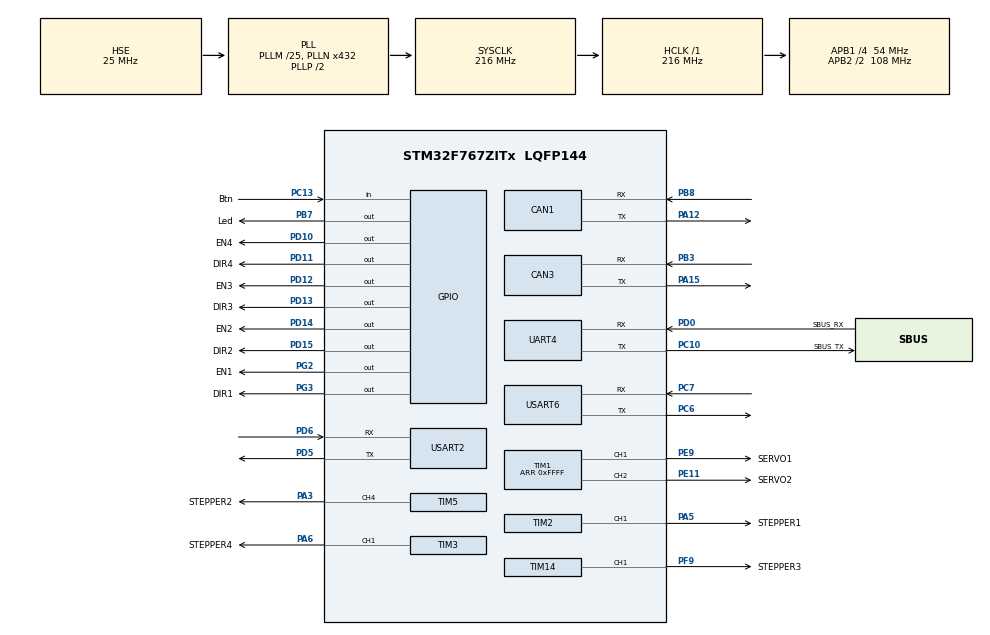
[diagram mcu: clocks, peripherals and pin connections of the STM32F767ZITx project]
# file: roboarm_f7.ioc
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CAN1.BS1=CAN_BS1_4TQ
CAN1.BS2=CAN_BS2_3TQ
CAN1.CalculateTimeQuantum=296.2962962962963
CAN3.BS1=CAN_BS1_4TQ
CAN3.BS2=CAN_BS2_3TQ
CAN3.CalculateTimeQuantum=296.2962962962963
Mcu.Family=STM32F7
Mcu.Name=STM32F767ZITx
Mcu.Package=LQFP144
NVIC.PriorityGroup=NVIC_PRIORITYGROUP_4
NVIC.TIM1_CC_IRQn=true\:0\:0\:false\:false\:true\:true\:true
PA12.Mode=Master
PA12.Signal=CAN1_TX
PA15.Mode=Master
PA15.Signal=CAN3_TX
PA3.GPIO_Label=STEPPER2
PA3.Signal=S_TIM5_CH4
PA5.GPIO_Label=STEPPER1
PA5.Signal=S_TIM2_CH1_ETR
PA6.GPIO_Label=STEPPER4
PA6.Signal=S_TIM3_CH1
PB3.Mode=Master
PB3.Signal=CAN3_RX
PB7.GPIO_FM7=__NULL
PB7.GPIO_Label=Led
PB7.GPIO_ModeDefaultOutputPP=GPIO_MODE_OUTPUT_PP
PB7.GPIO_PuPd=GPIO_NOPULL
PB7.GPIO_Speed=GPIO_SPEED_FREQ_LOW
PB7.PinState=GPIO_PIN_RESET
PB7.Signal=GPIO_Output
PB8.Mode=Master
PB8.Signal=CAN1_RX
PC10.GPIO_Label=SBUS_TX
PC10.Mode=Asynchronous
PC10.Signal=UART4_TX
PC13.GPIO_Label=Btn
PC13.GPIO_Mode=GPIO_MODE_INPUT
PC13.GPIO_PuPd=GPIO_NOPULL
PC13.Signal=GPIO_Input
PC6.Mode=Asynchronous
PC6.Signal=USART6_TX
PC7.Mode=Asynchronous
PC7.Signal=USART6_RX
PD0.GPIO_Label=SBUS_RX
PD0.Mode=Asynchronous
PD0.Signal=UART4_RX
PD10.GPIO_Label=EN4
PD10.Signal=GPIO_Output
PD11.GPIO_Label=DIR4
PD11.Signal=GPIO_Output
PD12.GPIO_Label=EN3
PD12.Signal=GPIO_Output
PD13.GPIO_Label=DIR3
PD13.Signal=GPIO_Output
PD14.GPIO_Label=EN2
PD14.Signal=GPIO_Output
PD15.GPIO_Label=DIR2
PD15.Signal=GPIO_Output
PD5.Mode=Asynchronous
PD5.Signal=USART2_TX
PD6.Mode=Asynchronous
PD6.Signal=USART2_RX
PE11.GPIO_Label=SERVO2
PE11.Signal=S_TIM1_CH2
PE9.GPIO_Label=SERVO1
PE9.Signal=S_TIM1_CH1
PF9.GPIO_Label=STEPPER3
PF9.Signal=S_TIM14_CH1
PG2.GPIO_Label=EN1
PG2.Signal=GPIO_Output
PG3.GPIO_Label=DIR1
PG3.Signal=GPIO_Output
PH0/OSC_IN.Mode=HSE-External-Oscillator
PH0/OSC_IN.Signal=RCC_OSC_IN
PH1/OSC_OUT.Mode=HSE-External-Oscillator
PH1/OSC_OUT.Signal=RCC_OSC_OUT
ProjectManager.HeapSize=0x200
ProjectManager.StackSize=0x400
ProjectManager.TargetToolchain=MDK-ARM V5
RCC.AHBFreq_Value=216000000
RCC.APB1CLKDivider=RCC_HCLK_DIV4
RCC.APB1Freq_Value=54000000
RCC.APB1TimFreq_Value=108000000
RCC.APB2CLKDivider=RCC_HCLK_DIV2
RCC.APB2Freq_Value=108000000
RCC.APB2TimFreq_Value=216000000
RCC.CortexFreq_Value=216000000
RCC.HCLKFreq_Value=216000000
RCC.HSE_VALUE=25000000
RCC.HSI_VALUE=16000000
RCC.LSE_VALUE=32768
RCC.PLLM=25
RCC.PLLN=432
RCC.PLLSourceVirtual=RCC_PLLSOURCE_HSE
RCC.SYSCLKFreq_VALUE=216000000
RCC.SYSCLKSource=RCC_SYSCLKSOURCE_PLLCLK
RCC.USBFreq_Value=216000000
RCC.VCOOutputFreq_Value=432000000
SH.S_TIM14_CH1.0=TIM14_CH1,PWM Generation1 CH1
SH.S_TIM1_CH1.0=TIM1_CH1,PWM Generation1 CH1
SH.S_TIM1_CH2.0=TIM1_CH2,PWM Generation2 CH2
SH.S_TIM2_CH1_ETR.0=TIM2_CH1,PWM Generation1 CH1
SH.S_TIM3_CH1.0=TIM3_CH1,PWM Generation1 CH1
SH.S_TIM5_CH4.0=TIM5_CH4,PWM Generation4 CH4
TIM1.Channel-PWM\ Generation1\ CH1=TIM_CHANNEL_1
TIM1.Channel-PWM\ Generation2\ CH2=TIM_CHANNEL_2
TIM1.Period=0xFFFF
TIM14.Channel=TIM_CHANNEL_1
TIM14.Prescaler=0xFFFF
TIM2.Channel-PWM\ Generation1\ CH1=TIM_CHANNEL_1
TIM2.Period=0xFFFF
TIM3.Channel-PWM\ Generation1\ CH1=TIM_CHANNEL_1
TIM3.Period=0xFFFF
TIM3.Prescaler=0x0
TIM5.Channel-PWM\ Generation4\ CH4=TIM_CHANNEL_4
TIM5.Period=0xFFFF
USART2.VirtualMode-Asynchronous=VM_ASYNC
USART6.VirtualMode-Asynchronous=VM_ASYNC
VP_TIM14_VS_ClockSourceINT.Mode=Enable_Timer
VP_TIM1_VS_ClockSourceINT.Mode=Internal
VP_TIM2_VS_ClockSourceINT.Mode=Internal
VP_TIM3_VS_ClockSourceINT.Mode=Internal
VP_TIM5_VS_ClockSourceINT.Mode=Internal
board=custom

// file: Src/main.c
/* USER CODE BEGIN Header */
/**
  ******************************************************************************
  * @file           : main.c
  * @brief          : Main program body
  ******************************************************************************
  * @attention
  *
  * <h2><center>&copy; Copyright (c) 2020 STMicroelectronics.
  * All rights reserved.</center></h2>
  *
  * This software component is licensed by ST under BSD 3-Clause license,
  * the "License"; You may not use this file except in compliance with the
  * License. You may obtain a copy of the License at:
  *                        opensource.org/licenses/BSD-3-Clause
  *
  ******************************************************************************
  */
/* USER CODE END Header */

#include "main.h"

CAN_HandleTypeDef hcan1;
CAN_HandleTypeDef hcan3;

TIM_HandleTypeDef htim1;
TIM_HandleTypeDef htim2;
TIM_HandleTypeDef htim3;
TIM_HandleTypeDef htim5;
TIM_HandleTypeDef htim14;

UART_HandleTypeDef huart4;
UART_HandleTypeDef huart2;
UART_HandleTypeDef huart6;

void SystemClock_Config(void);
static void MX_GPIO_Init(void);
static void MX_USART2_UART_Init(void);
static void MX_CAN1_Init(void);
static void MX_CAN3_Init(void);
static void MX_TIM1_Init(void);
static void MX_TIM2_Init(void);
static void MX_TIM3_Init(void);
static void MX_TIM5_Init(void);
static void MX_TIM14_Init(void);
static void MX_UART4_Init(void);
static void MX_USART6_UART_Init(void);

int main(void)
{
  /* USER CODE BEGIN 1 */
  int test = 0;
  int test2 = 0;
  /* USER CODE END 1 */

  /* MCU Configuration--------------------------------------------------------*/

  /* Reset of all peripherals, Initializes the Flash interface and the Systick. */
  HAL_Init();

  /* Configure the system clock */
  SystemClock_Config();

  /* Initialize all configured peripherals */
  MX_GPIO_Init();
  MX_USART2_UART_Init();
  MX_CAN1_Init();
  MX_CAN3_Init();
  MX_TIM1_Init();
  MX_TIM2_Init();
  MX_TIM3_Init();
  MX_TIM5_Init();
  MX_TIM14_Init();
  MX_UART4_Init();
  MX_USART6_UART_Init();

  /* Infinite loop */
  /* USER CODE BEGIN WHILE */
  while (1)
  {
    test = HAL_GetTick();
    test2 = 0;

    if((test != test2) == 0)
    {
      //HAL_GPIO_WritePin(Led_GPIO_Port, Led_Pin, GPIO_PIN_SET);
      HAL_GPIO_TogglePin(Led_GPIO_Port, Led_Pin);
      test2 = test;
      //HAL_UART_Transmit(&huart2, (uint8_t*)"ON\r\n", 3, 0xFFFF);
      //HAL_UART_Transmit(&huart6, (uint8_t*)"ON\r\n", 3, 0xFFFF);
    }
    else
    {
      //HAL_GPIO_WritePin(Led_GPIO_Port, Led_Pin, GPIO_PIN_RESET);
      //HAL_UART_Transmit(&huart2, (uint8_t*)"OFF\r\n", 4, 0xFFFF);
      //HAL_UART_Transmit(&huart6, (uint8_t*)"OFF\r\n", 4, 0xFFFF);
    }
    //HAL_Delay(100);
    /* USER CODE END WHILE */

  }
}

void SystemClock_Config(void)
{
  RCC_OscInitTypeDef RCC_OscInitStruct = {0};
  RCC_ClkInitTypeDef RCC_ClkInitStruct = {0};
  RCC_PeriphCLKInitTypeDef PeriphClkInitStruct = {0};

  /** Configure the main internal regulator output voltage
  */
  __HAL_RCC_PWR_CLK_ENABLE();
  __HAL_PWR_VOLTAGESCALING_CONFIG(PWR_REGULATOR_VOLTAGE_SCALE1);
  /** Initializes the CPU, AHB and APB busses clocks
  */
  RCC_OscInitStruct.OscillatorType = RCC_OSCILLATORTYPE_HSE;
  RCC_OscInitStruct.HSEState = RCC_HSE_ON;
  RCC_OscInitStruct.PLL.PLLState = RCC_PLL_ON;
  RCC_OscInitStruct.PLL.PLLSource = RCC_PLLSOURCE_HSE;
  RCC_OscInitStruct.PLL.PLLM = 25;
  RCC_OscInitStruct.PLL.PLLN = 432;
  RCC_OscInitStruct.PLL.PLLP = RCC_PLLP_DIV2;
  RCC_OscInitStruct.PLL.PLLQ = 2;
  if (HAL_RCC_OscConfig(&RCC_OscInitStruct) != HAL_OK)
  {
    Error_Handler();
  }
  /** Activate the Over-Drive mode
  */
  if (HAL_PWREx_EnableOverDrive() != HAL_OK)
  {
    Error_Handler();
  }
  /** Initializes the CPU, AHB and APB busses clocks
  */
  RCC_ClkInitStruct.ClockType = RCC_CLOCKTYPE_HCLK|RCC_CLOCKTYPE_SYSCLK
                              |RCC_CLOCKTYPE_PCLK1|RCC_CLOCKTYPE_PCLK2;
  RCC_ClkInitStruct.SYSCLKSource = RCC_SYSCLKSOURCE_PLLCLK;
  RCC_ClkInitStruct.AHBCLKDivider = RCC_SYSCLK_DIV1;
  RCC_ClkInitStruct.APB1CLKDivider = RCC_HCLK_DIV4;
  RCC_ClkInitStruct.APB2CLKDivider = RCC_HCLK_DIV2;

  if (HAL_RCC_ClockConfig(&RCC_ClkInitStruct, FLASH_LATENCY_7) != HAL_OK)
  {
    Error_Handler();
  }
  PeriphClkInitStruct.PeriphClockSelection = RCC_PERIPHCLK_USART2|RCC_PERIPHCLK_USART6
                              |RCC_PERIPHCLK_UART4;
  PeriphClkInitStruct.Usart2ClockSelection = RCC_USART2CLKSOURCE_PCLK1;
  PeriphClkInitStruct.Uart4ClockSelection = RCC_UART4CLKSOURCE_PCLK1;
  PeriphClkInitStruct.Usart6ClockSelection = RCC_USART6CLKSOURCE_PCLK2;
  if (HAL_RCCEx_PeriphCLKConfig(&PeriphClkInitStruct) != HAL_OK)
  {
    Error_Handler();
  }
}

static void MX_CAN1_Init(void)
{

  hcan1.Instance = CAN1;
  hcan1.Init.Prescaler = 16;
  hcan1.Init.Mode = CAN_MODE_NORMAL;
  hcan1.Init.SyncJumpWidth = CAN_SJW_1TQ;
  hcan1.Init.TimeSeg1 = CAN_BS1_4TQ;
  hcan1.Init.TimeSeg2 = CAN_BS2_3TQ;
  hcan1.Init.TimeTriggeredMode = DISABLE;
  hcan1.Init.AutoBusOff = DISABLE;
  hcan1.Init.AutoWakeUp = DISABLE;
  hcan1.Init.AutoRetransmission = DISABLE;
  hcan1.Init.ReceiveFifoLocked = DISABLE;
  hcan1.Init.TransmitFifoPriority = DISABLE;
  if (HAL_CAN_Init(&hcan1) != HAL_OK)
  {
    Error_Handler();
  }

}

static void MX_CAN3_Init(void)
{

  hcan3.Instance = CAN3;
  hcan3.Init.Prescaler = 16;
  hcan3.Init.Mode = CAN_MODE_NORMAL;
  hcan3.Init.SyncJumpWidth = CAN_SJW_1TQ;
  hcan3.Init.TimeSeg1 = CAN_BS1_4TQ;
  hcan3.Init.TimeSeg2 = CAN_BS2_3TQ;
  hcan3.Init.TimeTriggeredMode = DISABLE;
  hcan3.Init.AutoBusOff = DISABLE;
  hcan3.Init.AutoWakeUp = DISABLE;
  hcan3.Init.AutoRetransmission = DISABLE;
  hcan3.Init.ReceiveFifoLocked = DISABLE;
  hcan3.Init.TransmitFifoPriority = DISABLE;
  if (HAL_CAN_Init(&hcan3) != HAL_OK)
  {
    Error_Handler();
  }

}

static void MX_TIM1_Init(void)
{

  TIM_ClockConfigTypeDef sClockSourceConfig = {0};
  TIM_MasterConfigTypeDef sMasterConfig = {0};
  TIM_OC_InitTypeDef sConfigOC = {0};
  TIM_BreakDeadTimeConfigTypeDef sBreakDeadTimeConfig = {0};

  htim1.Instance = TIM1;
  htim1.Init.Prescaler = 0;
  htim1.Init.CounterMode = TIM_COUNTERMODE_UP;
  htim1.Init.Period = 0xFFFF;
  htim1.Init.ClockDivision = TIM_CLOCKDIVISION_DIV1;
  htim1.Init.RepetitionCounter = 0;
  htim1.Init.AutoReloadPreload = TIM_AUTORELOAD_PRELOAD_DISABLE;
  if (HAL_TIM_Base_Init(&htim1) != HAL_OK)
  {
    Error_Handler();
  }
  sClockSourceConfig.ClockSource = TIM_CLOCKSOURCE_INTERNAL;
  if (HAL_TIM_ConfigClockSource(&htim1, &sClockSourceConfig) != HAL_OK)
  {
    Error_Handler();
  }
  if (HAL_TIM_PWM_Init(&htim1) != HAL_OK)
  {
    Error_Handler();
  }
  sMasterConfig.MasterOutputTrigger = TIM_TRGO_RESET;
  sMasterConfig.MasterOutputTrigger2 = TIM_TRGO2_RESET;
  sMasterConfig.MasterSlaveMode = TIM_MASTERSLAVEMODE_DISABLE;
  if (HAL_TIMEx_MasterConfigSynchronization(&htim1, &sMasterConfig) != HAL_OK)
  {
    Error_Handler();
  }
  sConfigOC.OCMode = TIM_OCMODE_PWM1;
  sConfigOC.Pulse = 0;
  sConfigOC.OCPolarity = TIM_OCPOLARITY_HIGH;
  sConfigOC.OCNPolarity = TIM_OCNPOLARITY_HIGH;
  sConfigOC.OCFastMode = TIM_OCFAST_DISABLE;
  sConfigOC.OCIdleState = TIM_OCIDLESTATE_RESET;
  sConfigOC.OCNIdleState = TIM_OCNIDLESTATE_RESET;
  if (HAL_TIM_PWM_ConfigChannel(&htim1, &sConfigOC, TIM_CHANNEL_1) != HAL_OK)
  {
    Error_Handler();
  }
  if (HAL_TIM_PWM_ConfigChannel(&htim1, &sConfigOC, TIM_CHANNEL_2) != HAL_OK)
  {
    Error_Handler();
  }
  sBreakDeadTimeConfig.OffStateRunMode = TIM_OSSR_DISABLE;
  sBreakDeadTimeConfig.OffStateIDLEMode = TIM_OSSI_DISABLE;
  sBreakDeadTimeConfig.LockLevel = TIM_LOCKLEVEL_OFF;
  sBreakDeadTimeConfig.DeadTime = 0;
  sBreakDeadTimeConfig.BreakState = TIM_BREAK_DISABLE;
  sBreakDeadTimeConfig.BreakPolarity = TIM_BREAKPOLARITY_HIGH;
  sBreakDeadTimeConfig.BreakFilter = 0;
  sBreakDeadTimeConfig.Break2State = TIM_BREAK2_DISABLE;
  sBreakDeadTimeConfig.Break2Polarity = TIM_BREAK2POLARITY_HIGH;
  sBreakDeadTimeConfig.Break2Filter = 0;
  sBreakDeadTimeConfig.AutomaticOutput = TIM_AUTOMATICOUTPUT_DISABLE;
  if (HAL_TIMEx_ConfigBreakDeadTime(&htim1, &sBreakDeadTimeConfig) != HAL_OK)
  {
    Error_Handler();
  }
  HAL_TIM_MspPostInit(&htim1);

}

static void MX_TIM2_Init(void)
{

  TIM_ClockConfigTypeDef sClockSourceConfig = {0};
  TIM_MasterConfigTypeDef sMasterConfig = {0};
  TIM_OC_InitTypeDef sConfigOC = {0};

  htim2.Instance = TIM2;
  htim2.Init.Prescaler = 0;
  htim2.Init.CounterMode = TIM_COUNTERMODE_UP;
  htim2.Init.Period = 0xFFFF;
  htim2.Init.ClockDivision = TIM_CLOCKDIVISION_DIV1;
  htim2.Init.AutoReloadPreload = TIM_AUTORELOAD_PRELOAD_DISABLE;
  if (HAL_TIM_Base_Init(&htim2) != HAL_OK)
  {
    Error_Handler();
  }
  sClockSourceConfig.ClockSource = TIM_CLOCKSOURCE_INTERNAL;
  if (HAL_TIM_ConfigClockSource(&htim2, &sClockSourceConfig) != HAL_OK)
  {
    Error_Handler();
  }
  if (HAL_TIM_PWM_Init(&htim2) != HAL_OK)
  {
    Error_Handler();
  }
  sMasterConfig.MasterOutputTrigger = TIM_TRGO_RESET;
  sMasterConfig.MasterSlaveMode = TIM_MASTERSLAVEMODE_DISABLE;
  if (HAL_TIMEx_MasterConfigSynchronization(&htim2, &sMasterConfig) != HAL_OK)
  {
    Error_Handler();
  }
  sConfigOC.OCMode = TIM_OCMODE_PWM1;
  sConfigOC.Pulse = 0;
  sConfigOC.OCPolarity = TIM_OCPOLARITY_HIGH;
  sConfigOC.OCFastMode = TIM_OCFAST_DISABLE;
  if (HAL_TIM_PWM_ConfigChannel(&htim2, &sConfigOC, TIM_CHANNEL_1) != HAL_OK)
  {
    Error_Handler();
  }
  HAL_TIM_MspPostInit(&htim2);

}

static void MX_TIM3_Init(void)
{

  TIM_ClockConfigTypeDef sClockSourceConfig = {0};
  TIM_MasterConfigTypeDef sMasterConfig = {0};
  TIM_OC_InitTypeDef sConfigOC = {0};

  htim3.Instance = TIM3;
  htim3.Init.Prescaler = 0x0;
  htim3.Init.CounterMode = TIM_COUNTERMODE_UP;
  htim3.Init.Period = 0xFFFF;
  htim3.Init.ClockDivision = TIM_CLOCKDIVISION_DIV1;
  htim3.Init.AutoReloadPreload = TIM_AUTORELOAD_PRELOAD_DISABLE;
  if (HAL_TIM_Base_Init(&htim3) != HAL_OK)
  {
    Error_Handler();
  }
  sClockSourceConfig.ClockSource = TIM_CLOCKSOURCE_INTERNAL;
  if (HAL_TIM_ConfigClockSource(&htim3, &sClockSourceConfig) != HAL_OK)
  {
    Error_Handler();
  }
  if (HAL_TIM_PWM_Init(&htim3) != HAL_OK)
  {
    Error_Handler();
  }
  sMasterConfig.MasterOutputTrigger = TIM_TRGO_RESET;
  sMasterConfig.MasterSlaveMode = TIM_MASTERSLAVEMODE_DISABLE;
  if (HAL_TIMEx_MasterConfigSynchronization(&htim3, &sMasterConfig) != HAL_OK)
  {
    Error_Handler();
  }
  sConfigOC.OCMode = TIM_OCMODE_PWM1;
  sConfigOC.Pulse = 0;
  sConfigOC.OCPolarity = TIM_OCPOLARITY_HIGH;
  sConfigOC.OCFastMode = TIM_OCFAST_DISABLE;
  if (HAL_TIM_PWM_ConfigChannel(&htim3, &sConfigOC, TIM_CHANNEL_1) != HAL_OK)
  {
    Error_Handler();
  }
  HAL_TIM_MspPostInit(&htim3);

}

static void MX_TIM5_Init(void)
{

  TIM_ClockConfigTypeDef sClockSourceConfig = {0};
  TIM_MasterConfigTypeDef sMasterConfig = {0};
  TIM_OC_InitTypeDef sConfigOC = {0};

  htim5.Instance = TIM5;
  htim5.Init.Prescaler = 0;
  htim5.Init.CounterMode = TIM_COUNTERMODE_UP;
  htim5.Init.Period = 0xFFFF;
  htim5.Init.ClockDivision = TIM_CLOCKDIVISION_DIV1;
  htim5.Init.AutoReloadPreload = TIM_AUTORELOAD_PRELOAD_DISABLE;
  if (HAL_TIM_Base_Init(&htim5) != HAL_OK)
  {
    Error_Handler();
  }
  sClockSourceConfig.ClockSource = TIM_CLOCKSOURCE_INTERNAL;
  if (HAL_TIM_ConfigClockSource(&htim5, &sClockSourceConfig) != HAL_OK)
  {
    Error_Handler();
  }
  if (HAL_TIM_PWM_Init(&htim5) != HAL_OK)
  {
    Error_Handler();
  }
  sMasterConfig.MasterOutputTrigger = TIM_TRGO_RESET;
  sMasterConfig.MasterSlaveMode = TIM_MASTERSLAVEMODE_DISABLE;
  if (HAL_TIMEx_MasterConfigSynchronization(&htim5, &sMasterConfig) != HAL_OK)
  {
    Error_Handler();
  }
  sConfigOC.OCMode = TIM_OCMODE_PWM1;
  sConfigOC.Pulse = 0;
  sConfigOC.OCPolarity = TIM_OCPOLARITY_HIGH;
  sConfigOC.OCFastMode = TIM_OCFAST_DISABLE;
  if (HAL_TIM_PWM_ConfigChannel(&htim5, &sConfigOC, TIM_CHANNEL_4) != HAL_OK)
  {
    Error_Handler();
  }
  HAL_TIM_MspPostInit(&htim5);

}

static void MX_TIM14_Init(void)
{

  TIM_OC_InitTypeDef sConfigOC = {0};

  htim14.Instance = TIM14;
  htim14.Init.Prescaler = 0xFFFF;
  htim14.Init.CounterMode = TIM_COUNTERMODE_UP;
  htim14.Init.Period = 0;
  htim14.Init.ClockDivision = TIM_CLOCKDIVISION_DIV1;
  htim14.Init.AutoReloadPreload = TIM_AUTORELOAD_PRELOAD_DISABLE;
  if (HAL_TIM_Base_Init(&htim14) != HAL_OK)
  {
    Error_Handler();
  }
  if (HAL_TIM_PWM_Init(&htim14) != HAL_OK)
  {
    Error_Handler();
  }
  sConfigOC.OCMode = TIM_OCMODE_PWM1;
  sConfigOC.Pulse = 0;
  sConfigOC.OCPolarity = TIM_OCPOLARITY_HIGH;
  sConfigOC.OCFastMode = TIM_OCFAST_DISABLE;
  if (HAL_TIM_PWM_ConfigChannel(&htim14, &sConfigOC, TIM_CHANNEL_1) != HAL_OK)
  {
    Error_Handler();
  }
  HAL_TIM_MspPostInit(&htim14);

}

static void MX_UART4_Init(void)
{

  huart4.Instance = UART4;
  huart4.Init.BaudRate = 115200;
  huart4.Init.WordLength = UART_WORDLENGTH_8B;
  huart4.Init.StopBits = UART_STOPBITS_1;
  huart4.Init.Parity = UART_PARITY_NONE;
  huart4.Init.Mode = UART_MODE_TX_RX;
  huart4.Init.HwFlowCtl = UART_HWCONTROL_NONE;
  huart4.Init.OverSampling = UART_OVERSAMPLING_16;
  huart4.Init.OneBitSampling = UART_ONE_BIT_SAMPLE_DISABLE;
  huart4.AdvancedInit.AdvFeatureInit = UART_ADVFEATURE_NO_INIT;
  if (HAL_UART_Init(&huart4) != HAL_OK)
  {
    Error_Handler();
  }

}

static void MX_USART2_UART_Init(void)
{

  huart2.Instance = USART2;
  huart2.Init.BaudRate = 115200;
  huart2.Init.WordLength = UART_WORDLENGTH_8B;
  huart2.Init.StopBits = UART_STOPBITS_1;
  huart2.Init.Parity = UART_PARITY_NONE;
  huart2.Init.Mode = UART_MODE_TX_RX;
  huart2.Init.HwFlowCtl = UART_HWCONTROL_NONE;
  huart2.Init.OverSampling = UART_OVERSAMPLING_16;
  huart2.Init.OneBitSampling = UART_ONE_BIT_SAMPLE_DISABLE;
  huart2.AdvancedInit.AdvFeatureInit = UART_ADVFEATURE_NO_INIT;
  if (HAL_UART_Init(&huart2) != HAL_OK)
  {
    Error_Handler();
  }

}

static void MX_USART6_UART_Init(void)
{

  huart6.Instance = USART6;
  huart6.Init.BaudRate = 115200;
  huart6.Init.WordLength = UART_WORDLENGTH_8B;
  huart6.Init.StopBits = UART_STOPBITS_1;
  huart6.Init.Parity = UART_PARITY_NONE;
  huart6.Init.Mode = UART_MODE_TX_RX;
  huart6.Init.HwFlowCtl = UART_HWCONTROL_NONE;
  huart6.Init.OverSampling = UART_OVERSAMPLING_16;
  huart6.Init.OneBitSampling = UART_ONE_BIT_SAMPLE_DISABLE;
  huart6.AdvancedInit.AdvFeatureInit = UART_ADVFEATURE_NO_INIT;
  if (HAL_UART_Init(&huart6) != HAL_OK)
  {
    Error_Handler();
  }

}

static void MX_GPIO_Init(void)
{
  GPIO_InitTypeDef GPIO_InitStruct = {0};

  /* GPIO Ports Clock Enable */
  __HAL_RCC_GPIOC_CLK_ENABLE();
  __HAL_RCC_GPIOF_CLK_ENABLE();
  __HAL_RCC_GPIOH_CLK_ENABLE();
  __HAL_RCC_GPIOA_CLK_ENABLE();
  __HAL_RCC_GPIOE_CLK_ENABLE();
  __HAL_RCC_GPIOD_CLK_ENABLE();
  __HAL_RCC_GPIOG_CLK_ENABLE();
  __HAL_RCC_GPIOB_CLK_ENABLE();

  /*Configure GPIO pin Output Level */
  HAL_GPIO_WritePin(GPIOD, EN4_Pin|DIR4_Pin|EN3_Pin|DIR3_Pin
                          |EN2_Pin|DIR2_Pin, GPIO_PIN_RESET);

  /*Configure GPIO pin Output Level */
  HAL_GPIO_WritePin(GPIOG, EN1_Pin|DIR1_Pin, GPIO_PIN_RESET);

  /*Configure GPIO pin Output Level */
  HAL_GPIO_WritePin(Led_GPIO_Port, Led_Pin, GPIO_PIN_RESET);

  /*Configure GPIO pin : Btn_Pin */
  GPIO_InitStruct.Pin = Btn_Pin;
  GPIO_InitStruct.Mode = GPIO_MODE_INPUT;
  GPIO_InitStruct.Pull = GPIO_NOPULL;
  HAL_GPIO_Init(Btn_GPIO_Port, &GPIO_InitStruct);

  /*Configure GPIO pins : EN4_Pin DIR4_Pin EN3_Pin DIR3_Pin
                           EN2_Pin DIR2_Pin */
  GPIO_InitStruct.Pin = EN4_Pin|DIR4_Pin|EN3_Pin|DIR3_Pin
                          |EN2_Pin|DIR2_Pin;
  GPIO_InitStruct.Mode = GPIO_MODE_OUTPUT_PP;
  GPIO_InitStruct.Pull = GPIO_NOPULL;
  GPIO_InitStruct.Speed = GPIO_SPEED_FREQ_LOW;
  HAL_GPIO_Init(GPIOD, &GPIO_InitStruct);

  /*Configure GPIO pins : EN1_Pin DIR1_Pin */
  GPIO_InitStruct.Pin = EN1_Pin|DIR1_Pin;
  GPIO_InitStruct.Mode = GPIO_MODE_OUTPUT_PP;
  GPIO_InitStruct.Pull = GPIO_NOPULL;
  GPIO_InitStruct.Speed = GPIO_SPEED_FREQ_LOW;
  HAL_GPIO_Init(GPIOG, &GPIO_InitStruct);

  /*Configure GPIO pin : Led_Pin */
  GPIO_InitStruct.Pin = Led_Pin;
  GPIO_InitStruct.Mode = GPIO_MODE_OUTPUT_PP;
  GPIO_InitStruct.Pull = GPIO_NOPULL;
  GPIO_InitStruct.Speed = GPIO_SPEED_FREQ_LOW;
  HAL_GPIO_Init(Led_GPIO_Port, &GPIO_InitStruct);

}

void Error_Handler(void)
{
}

/************************ (C) COPYRIGHT STMicroelectronics *****END OF FILE****/
